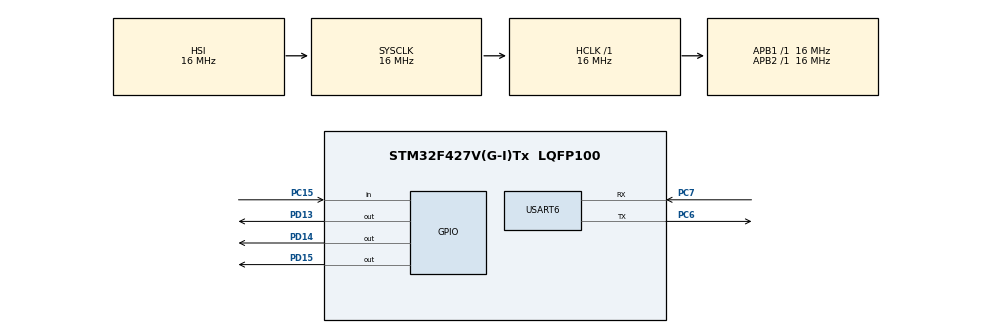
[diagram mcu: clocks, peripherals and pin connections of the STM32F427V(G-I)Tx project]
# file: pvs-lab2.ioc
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Mcu.Family=STM32F4
Mcu.Name=STM32F427V(G-I)Tx
Mcu.Package=LQFP100
NVIC.PriorityGroup=NVIC_PRIORITYGROUP_4
NVIC.USART6_IRQn=true\:0\:0\:false\:false\:true\:true\:true\:true
PC15/OSC32_OUT.Signal=GPIO_Input
PC6.Mode=Asynchronous
PC6.Signal=USART6_TX
PC7.Mode=Asynchronous
PC7.Signal=USART6_RX
PD13.Signal=GPIO_Output
PD14.Signal=GPIO_Output
PD15.Signal=GPIO_Output
ProjectManager.HeapSize=0x200
ProjectManager.StackSize=0x400
ProjectManager.TargetToolchain=STM32CubeIDE
RCC.AHBFreq_Value=16000000
RCC.APB1Freq_Value=16000000
RCC.APB2Freq_Value=16000000
RCC.CortexFreq_Value=16000000
RCC.HSE_VALUE=25000000
RCC.HSI_VALUE=16000000
RCC.LSE_VALUE=32768
RCC.SYSCLKFreq_VALUE=16000000
RCC.VCOOutputFreq_Value=192000000
USART6.VirtualMode=VM_ASYNC
board=custom

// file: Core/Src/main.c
/* USER CODE BEGIN Header */
/**
  ******************************************************************************
  * @file           : main.c
  * @brief          : Main program body
  ******************************************************************************
  * @attention
  *
  * Copyright (c) 2025 STMicroelectronics.
  * All rights reserved.
  *
  * This software is licensed under terms that can be found in the LICENSE file
  * in the root directory of this software component.
  * If no LICENSE file comes with this software, it is provided AS-IS.
  *
  ******************************************************************************
  */
/* USER CODE END Header */
#include "main.h"
#include "usart.h"
#include "gpio.h"

/* USER CODE BEGIN Includes */
#include "command.h"
#include "stdarg.h"
#include "stm32_io.h"
#include "garland.h"
/* USER CODE END Includes */

void SystemClock_Config(void);

int main(void)
{

  /* MCU Configuration--------------------------------------------------------*/

  /* Reset of all peripherals, Initializes the Flash interface and the Systick. */
  HAL_Init();

  /* Configure the system clock */
  SystemClock_Config();

  /* Initialize all configured peripherals */
  MX_GPIO_Init();
  MX_USART6_UART_Init();
  /* USER CODE BEGIN 2 */

  start_receive_char_it();

  /* USER CODE END 2 */

  /* Infinite loop */
  /* USER CODE BEGIN WHILE */
  while (1) {
    garland_button_processing();
    garland_ignite();
	  read_char(command_execute);
    /* USER CODE END WHILE */

    }
}

void SystemClock_Config(void)
{
  RCC_OscInitTypeDef RCC_OscInitStruct = {0};
  RCC_ClkInitTypeDef RCC_ClkInitStruct = {0};

  /** Configure the main internal regulator output voltage
  */
  __HAL_RCC_PWR_CLK_ENABLE();
  __HAL_PWR_VOLTAGESCALING_CONFIG(PWR_REGULATOR_VOLTAGE_SCALE3);

  /** Initializes the RCC Oscillators according to the specified parameters
  * in the RCC_OscInitTypeDef structure.
  */
  RCC_OscInitStruct.OscillatorType = RCC_OSCILLATORTYPE_HSI;
  RCC_OscInitStruct.HSIState = RCC_HSI_ON;
  RCC_OscInitStruct.HSICalibrationValue = RCC_HSICALIBRATION_DEFAULT;
  RCC_OscInitStruct.PLL.PLLState = RCC_PLL_NONE;
  if (HAL_RCC_OscConfig(&RCC_OscInitStruct) != HAL_OK)
  {
    Error_Handler();
  }

  /** Initializes the CPU, AHB and APB buses clocks
  */
  RCC_ClkInitStruct.ClockType = RCC_CLOCKTYPE_HCLK|RCC_CLOCKTYPE_SYSCLK
                              |RCC_CLOCKTYPE_PCLK1|RCC_CLOCKTYPE_PCLK2;
  RCC_ClkInitStruct.SYSCLKSource = RCC_SYSCLKSOURCE_HSI;
  RCC_ClkInitStruct.AHBCLKDivider = RCC_SYSCLK_DIV1;
  RCC_ClkInitStruct.APB1CLKDivider = RCC_HCLK_DIV1;
  RCC_ClkInitStruct.APB2CLKDivider = RCC_HCLK_DIV1;

  if (HAL_RCC_ClockConfig(&RCC_ClkInitStruct, FLASH_LATENCY_0) != HAL_OK)
  {
    Error_Handler();
  }
}

void Error_Handler(void)
{
  __disable_irq();
  while (1)
  {
  }
}
